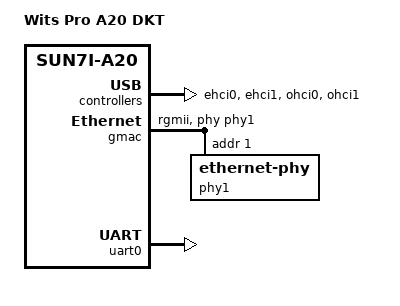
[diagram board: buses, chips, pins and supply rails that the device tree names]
/*
 * Copyright 2015 Hans de Goede <hdegoede@redhat.com>
 *
 * Minimal dts file for the Wits Pro A20 DKT for u-boot only
 *
 * SPDX-License-Identifier:     GPL-2.0+ or X11
 */

/dts-v1/;
#include "sun7i-a20.dtsi"

/ {
	model = "Wits Pro A20 DKT";
	compatible = "wits,pro-a20-dkt", "allwinner,sun7i-a20";

	aliases {
		serial0 = &uart0;
	};

	chosen {
		stdout-path = "serial0:115200n8";
	};
};

&ehci0 {
	status = "okay";
};

&ehci1 {
	status = "okay";
};

&gmac {
	pinctrl-names = "default";
	pinctrl-0 = <&gmac_pins_rgmii_a>;
	phy = <&phy1>;
	phy-mode = "rgmii";
	status = "okay";

	phy1: ethernet-phy@1 {
		reg = <1>;
	};
};

&ohci0 {
	status = "okay";
};

&ohci1 {
	status = "okay";
};

&uart0 {
	pinctrl-names = "default";
	pinctrl-0 = <&uart0_pins_a>;
	status = "okay";
};
